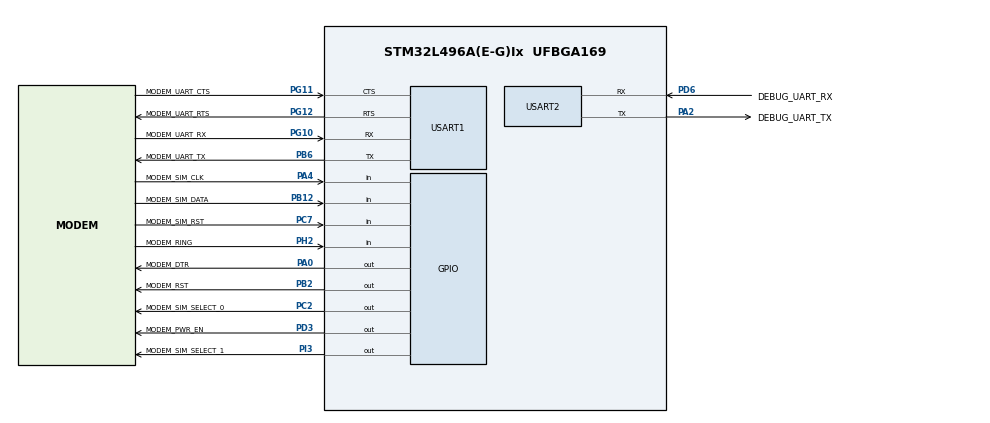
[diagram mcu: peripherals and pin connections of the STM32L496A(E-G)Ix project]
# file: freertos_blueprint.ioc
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FREERTOS.INCLUDE_vTaskDelayUntil=1
FREERTOS.MEMORY_ALLOCATION=0
FREERTOS.Tasks01=defaultTask,0,128,StartDefaultTask,Default,NULL,Dynamic,NULL,NULL
FREERTOS.configENABLE_BACKWARD_COMPATIBILITY=1
FREERTOS.configUSE_COUNTING_SEMAPHORES=1
FREERTOS.configUSE_NEWLIB_REENTRANT=0
FREERTOS.configUSE_TIMERS=1
FREERTOS.configUSE_TRACE_FACILITY=1
Mcu.Family=STM32L4
Mcu.Name=STM32L496A(E-G)Ix
Mcu.Package=UFBGA169
NVIC.PriorityGroup=NVIC_PRIORITYGROUP_4
NVIC.TIM6_DAC_IRQn=true\:0\:0\:true\:false\:true\:false\:false\:true\:true
NVIC.TimeBase=TIM6_DAC_IRQn
NVIC.TimeBaseIP=TIM6
NVIC.USART1_IRQn=true\:5\:0\:false\:false\:true\:true\:true\:true\:true
NVIC.USART2_IRQn=true\:5\:0\:false\:false\:true\:true\:true\:true\:true
PA0.GPIO_Label=MODEM_DTR
PA0.Signal=GPIO_Output
PA2.GPIO_Label=DEBUG_UART_TX
PA2.Mode=Asynchronous
PA2.Signal=USART2_TX
PA4.GPIO_Label=MODEM_SIM_CLK
PA4.Signal=GPIO_Input
PB12.GPIO_Label=MODEM_SIM_DATA
PB12.Signal=GPIO_Input
PB2.GPIO_Label=MODEM_RST
PB2.PinState=GPIO_PIN_SET
PB2.Signal=GPIO_Output
PB6.GPIO_Label=MODEM_UART_TX
PB6.Mode=Asynchronous
PB6.Signal=USART1_TX
PC2.GPIO_Label=MODEM_SIM_SELECT_0
PC2.Signal=GPIO_Output
PC7.GPIO_Label=MODEM_SIM_RST
PC7.Signal=GPIO_Input
PD3.GPIO_Label=MODEM_PWR_EN
PD3.PinState=GPIO_PIN_SET
PD3.Signal=GPIO_Output
PD6.GPIO_Label=DEBUG_UART_RX
PD6.Mode=Asynchronous
PD6.Signal=USART2_RX
PG10.GPIO_Label=MODEM_UART_RX
PG10.Mode=Asynchronous
PG10.Signal=USART1_RX
PG11.GPIO_Label=MODEM_UART_CTS
PG11.Mode=CTS_RTS
PG11.Signal=USART1_CTS
PG12.GPIO_Label=MODEM_UART_RTS
PG12.Mode=CTS_RTS
PG12.Signal=USART1_RTS
PH2.GPIO_Label=MODEM_RING
PH2.Signal=GPIO_Input
PI3.GPIO_Label=MODEM_SIM_SELECT_1
PI3.Signal=GPIO_Output
ProjectManager.HeapSize=0x200
ProjectManager.StackSize=0x400
ProjectManager.TargetToolchain=CMake
RCC.ADCFreq_Value=40000000
RCC.AHBFreq_Value=80000000
RCC.APB1Freq_Value=80000000
RCC.APB1TimFreq_Value=80000000
RCC.APB2Freq_Value=80000000
RCC.APB2TimFreq_Value=80000000
RCC.CortexFreq_Value=80000000
RCC.HCLKFreq_Value=80000000
RCC.HSE_VALUE=8000000
RCC.HSI48_VALUE=48000000
RCC.HSI_VALUE=16000000
RCC.LSE_VALUE=32768
RCC.MSI_VALUE=4000000
RCC.PLLN=40
RCC.PLLSAI1N=20
RCC.SYSCLKFreq_VALUE=80000000
RCC.SYSCLKSource=RCC_SYSCLKSOURCE_PLLCLK
RCC.USBFreq_Value=40000000
RCC.VCOOutputFreq_Value=160000000
USART1.VirtualMode-Asynchronous=VM_ASYNC
USART2.VirtualMode-Asynchronous=VM_ASYNC
VP_FREERTOS_VS_CMSIS_V1.Mode=CMSIS_V1
VP_RNG_VS_RNG.Mode=RNG_Activate
VP_RTC_VS_RTC_Activate.Mode=RTC_Enabled
VP_SYS_VS_tim6.Mode=TIM6
board=custom

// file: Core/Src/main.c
/* USER CODE BEGIN Header */

/**
 ******************************************************************************
 * @file           : main.c
 * @brief          : Main program body
 ******************************************************************************
 * @attention
 *
 * <h2><center>&copy; Copyright (c) 2020 STMicroelectronics.
 * All rights reserved.</center></h2>
 *
 * This software component is licensed by ST under Ultimate Liberty license
 * SLA0044, the "License"; You may not use this file except in compliance with
 * the License. You may obtain a copy of the License at:
 *                             www.st.com/SLA0044
 *
 ******************************************************************************
 */
/* USER CODE END Header */
#include "iot_config.h"

#include "main.h"
#include "stdint.h"
#include "stdarg.h"

/* FreeRTOS includes. */
#include "FreeRTOS.h"
#include "task.h"
/* Demo Includes*/
#include "cellular_app.h"

#ifdef IOT_LOG_LEVEL_MAIN
#else
    #ifdef IOT_LOG_LEVEL_GLOBAL
        #define LIBRARY_LOG_LEVEL    IOT_LOG_LEVEL_GLOBAL
    #else
        #define LIBRARY_LOG_LEVEL    IOT_LOG_DEBUG
    #endif
#endif
/*#include "cmsis_os.h" */
/*#include "i2c.h" */
#include "usart.h"
#include "rng.h"
#include "rtc.h"
#include "gpio.h"

#define MAX_RETRY_ATTEMPTS    5      /* Maximum number of retries */
#define RETRY_DELAY_MS        10000  /* Delay between retry attempts in milliseconds */

/* The SPI driver polls at a high priority. The logging task's priority must also
 * be high to be not be starved of CPU time. */
#define mainLOGGING_TASK_PRIORITY           ( configMAX_PRIORITIES )
#define mainLOGGING_TASK_STACK_SIZE         ( configMINIMAL_STACK_SIZE * 4 )
#define mainLOGGING_MESSAGE_QUEUE_LENGTH    ( 15 )
#define main_RUNNER_TASK_STACK_SIZE         ( configMINIMAL_STACK_SIZE * 8 )

/* Heap 2 size for malloc. */
#define HEAP2_SIZE    ( 27 * 1024 )
void vApplicationDaemonTaskStartupHook( void );
extern void RunDemoTask( void );
extern int setupCellular( void );

/**********************
* Global Variables
**********************/
RTC_HandleTypeDef xHrtc;
RNG_HandleTypeDef xHrng;
uint8_t payload_selector;

int32_t delay_publish = 60 * 1000;

static void SystemClock_Config( void );

/**
 * @brief Initializes the STM32L475 IoT node board.
 *
 * Initialization of clock, LEDs, RNG, RTC, and Cellular module.
 */
static void prvMiscInitialization( void );

/**
 * @brief Initializes the FreeRTOS heap.
 *
 * Heap_5 is being used because the RAM is not contiguous, therefore the heap
 * needs to be initialized.  See http://www.freertos.org/a00111.html
 */
static void prvInitializeHeap( void );

/* USER CODE END PD */

void SystemClock_Config( void );
void MX_FREERTOS_Init( void );

static void CellularDemoTask()
{
    bool retCellular = true;

    /* Setup cellular. */
    retCellular = setupCellular();

    if( !retCellular )
    {
        int retries = 0;

        /* Retry cellular setup with a maximum number of attempts */
        while( ( retries < MAX_RETRY_ATTEMPTS ) && ( !retCellular ) )
        {
            /* Set pin PD3 to high, signaling the attempt */
            HAL_GPIO_WritePin( GPIOD, GPIO_PIN_3, GPIO_PIN_SET );

            /* Delay between retries */
            HAL_Delay( RETRY_DELAY_MS );

            /* Attempt to set up the cellular connection */
            retCellular = setupCellular();

            retries++;
        }

        /* If still unsuccessful after retries, prompt user for manual intervention */
        if( !retCellular )
        {
            /* Optionally, reset the system if necessary (uncomment if used) */
            LogInfo( "System will reset to resolve the issue.\r\n" );
            HAL_NVIC_SystemReset();
            return;
        }
    }

/* Stop here if we fail to initialize cellular. */
    configASSERT( retCellular == true );

    LogInfo( "---- START DEMO : ----- .\r\n" );

    RunDemoTask();
}

int main( void )
{
    /* Perform any hardware initialization that does not require the RTOS to be
     * running.  */
    prvMiscInitialization();

    /* MCU Configuration--------------------------------------------------------*/

    /* Reset of all peripherals, Initializes the Flash interface and the Systick. */
    HAL_Init();

    /* Configure the system clock */
    SystemClock_Config();

    /* Create tasks that are not dependent on the Cellular being initialized. */
    xLoggingTaskInitialize( mainLOGGING_TASK_STACK_SIZE,
                            mainLOGGING_TASK_PRIORITY,
                            mainLOGGING_MESSAGE_QUEUE_LENGTH );

    /* Start the scheduler.  Initialization that requires the OS to be running,
     */
    vTaskStartScheduler();

    return 0;
}

/*-----------------------------------------------------------*/

void vApplicationDaemonTaskStartupHook( void )
{
    if( SYSTEM_Init() == pdPASS )
    {
        xTaskCreate( CellularDemoTask,            /* Function that implements the task. */
                     "CellularDemo",              /* Text name for the task - only used for debugging. */
                     main_RUNNER_TASK_STACK_SIZE, /* Size of stack (in words, not bytes) to allocate for the task. */
                     NULL,                        /* Task parameter - not used in this case. */
                     configMAX_PRIORITIES - 2,    /* Task priority, must be between 0 and configMAX_PRIORITIES - 1. */
                     NULL );                      /* Used to pass out a handle to the created task - not used in this case. */
    }
    else
    {
        IotLogError( "System failed to initialize.\r\n" );
        return;
    }
}
/*-----------------------------------------------------------*/

/**
 * @brief Initializes the board.
 */
static void prvMiscInitialization( void )
{
    /* Reset of all peripherals, Initializes the Flash interface and the Systick. */
    HAL_Init();

    /* Configure the system clock. */
    SystemClock_Config();

    /* Heap_5 is being used because the RAM is not contiguous in memory, so the
     * heap must be initialized. */
    prvInitializeHeap();

    /* Initialize all configured peripherals */
    MX_GPIO_Init();
    MX_USART2_UART_Init();

    /* Disable initialization of Modem-UART.
     * It will be enabled only when requested by upper layers.
     * MX_USART1_UART_Init();
     */
    MX_USART1_UART_Init();
    MX_RTC_Init();
    MX_RNG_Init();
}

/*-----------------------------------------------------------*/

/* Psuedo random number generator.  Just used by demos so does not need to be
 * secure.  Do not use the standard C library rand() function as it can cause
 * unexpected behaviour, such as calls to malloc(). */
int iMainRand32( void )
{
    static UBaseType_t uxlNextRand; /*_RB_ Not seeded. */
    const uint32_t ulMultiplier = 0x015a4e35UL, ulIncrement = 1UL;

    /* Utility function to generate a pseudo random number. */

    uxlNextRand = ( ulMultiplier * uxlNextRand ) + ulIncrement;

    return( ( int ) ( uxlNextRand >> 16UL ) & 0x7fffUL );
}

static void prvInitializeHeap( void )
{
    static uint8_t ucHeap1[ configTOTAL_HEAP_SIZE ];
    static uint8_t ucHeap2[ HEAP2_SIZE ] __attribute__( ( section( ".freertos_heap2" ) ) );

    HeapRegion_t xHeapRegions[] =
    {
        { ( unsigned char * ) ucHeap2, sizeof( ucHeap2 ) },
        { ( unsigned char * ) ucHeap1, sizeof( ucHeap1 ) },
        { NULL,                        0                 }
    };

    vPortDefineHeapRegions( xHeapRegions );
}

/*-----------------------------------------------------------*/

void SystemClock_Config( void )
{
    RCC_OscInitTypeDef RCC_OscInitStruct = { 0 };
    RCC_ClkInitTypeDef RCC_ClkInitStruct = { 0 };
    RCC_PeriphCLKInitTypeDef PeriphClkInit = { 0 };

    /** Initializes the CPU, AHB and APB busses clocks
     */
    RCC_OscInitStruct.OscillatorType = RCC_OSCILLATORTYPE_LSI | RCC_OSCILLATORTYPE_MSI;
    RCC_OscInitStruct.LSIState = RCC_LSI_ON;
    RCC_OscInitStruct.MSIState = RCC_MSI_ON;
    RCC_OscInitStruct.MSICalibrationValue = 0;
    RCC_OscInitStruct.MSIClockRange = RCC_MSIRANGE_6;
    RCC_OscInitStruct.PLL.PLLState = RCC_PLL_ON;
    RCC_OscInitStruct.PLL.PLLSource = RCC_PLLSOURCE_MSI;
    RCC_OscInitStruct.PLL.PLLM = 1;
    RCC_OscInitStruct.PLL.PLLN = 40;
    RCC_OscInitStruct.PLL.PLLP = RCC_PLLP_DIV2;
    RCC_OscInitStruct.PLL.PLLQ = RCC_PLLQ_DIV2;
    RCC_OscInitStruct.PLL.PLLR = RCC_PLLR_DIV2;

    if( HAL_RCC_OscConfig( &RCC_OscInitStruct ) != HAL_OK )
    {
        Error_Handler();
    }

    /** Initializes the CPU, AHB and APB busses clocks
     */
    RCC_ClkInitStruct.ClockType = RCC_CLOCKTYPE_HCLK | RCC_CLOCKTYPE_SYSCLK
                                  | RCC_CLOCKTYPE_PCLK1 | RCC_CLOCKTYPE_PCLK2;
    RCC_ClkInitStruct.SYSCLKSource = RCC_SYSCLKSOURCE_PLLCLK;
    RCC_ClkInitStruct.AHBCLKDivider = RCC_SYSCLK_DIV1;
    RCC_ClkInitStruct.APB1CLKDivider = RCC_HCLK_DIV1;
    RCC_ClkInitStruct.APB2CLKDivider = RCC_HCLK_DIV1;

    if( HAL_RCC_ClockConfig( &RCC_ClkInitStruct, FLASH_LATENCY_4 ) != HAL_OK )
    {
        Error_Handler();
    }

    PeriphClkInit.PeriphClockSelection = RCC_PERIPHCLK_RTC | RCC_PERIPHCLK_USART1
                                         | RCC_PERIPHCLK_USART2 | RCC_PERIPHCLK_LPUART1
                                         | RCC_PERIPHCLK_I2C1 | RCC_PERIPHCLK_RNG;

    PeriphClkInit.Usart1ClockSelection = RCC_USART1CLKSOURCE_PCLK2;
    PeriphClkInit.Usart2ClockSelection = RCC_USART2CLKSOURCE_PCLK1;
    PeriphClkInit.Lpuart1ClockSelection = RCC_LPUART1CLKSOURCE_PCLK1;
    PeriphClkInit.I2c1ClockSelection = RCC_I2C1CLKSOURCE_PCLK1;
    PeriphClkInit.RTCClockSelection = RCC_RTCCLKSOURCE_LSI;
    PeriphClkInit.RngClockSelection = RCC_RNGCLKSOURCE_PLLSAI1;
    PeriphClkInit.PLLSAI1.PLLSAI1Source = RCC_PLLSOURCE_MSI;
    PeriphClkInit.PLLSAI1.PLLSAI1M = 1;
    PeriphClkInit.PLLSAI1.PLLSAI1N = 20;
    PeriphClkInit.PLLSAI1.PLLSAI1P = RCC_PLLP_DIV2;
    PeriphClkInit.PLLSAI1.PLLSAI1Q = RCC_PLLQ_DIV2;
    PeriphClkInit.PLLSAI1.PLLSAI1R = RCC_PLLR_DIV2;
    PeriphClkInit.PLLSAI1.PLLSAI1ClockOut = RCC_PLLSAI1_48M2CLK;

    if( HAL_RCCEx_PeriphCLKConfig( &PeriphClkInit ) != HAL_OK )
    {
        Error_Handler();
    }

    /** Configure the main internal regulator output voltage
     */
    if( HAL_PWREx_ControlVoltageScaling( PWR_REGULATOR_VOLTAGE_SCALE1 ) != HAL_OK )
    {
        Error_Handler();
    }

    /**Configure the Systick interrupt time
     */
    HAL_SYSTICK_Config( HAL_RCC_GetHCLKFreq() / 1000 );

    /**Configure the Systick
     */
    HAL_SYSTICK_CLKSourceConfig( SYSTICK_CLKSOURCE_HCLK );

    /* SysTick_IRQn interrupt configuration */
    HAL_NVIC_SetPriority( SysTick_IRQn, 15, 0 );
}

/*-----------------------------------------------------------*/

void vApplicationIdleHook( void )
{
    static TickType_t xLastPrint = 0;
    TickType_t xTimeNow;
    const TickType_t xPrintFrequency = pdMS_TO_TICKS( 30000 );

    xTimeNow = xTaskGetTickCount();

    if( ( xTimeNow - xLastPrint ) > xPrintFrequency )
    {
        IotLogInfo( "." );
        xLastPrint = xTimeNow;
    }
}

void HAL_TIM_PeriodElapsedCallback( TIM_HandleTypeDef * htim )
{
    if( htim->Instance == TIM3 )
    {
        HAL_IncTick();
    }
}

void Error_Handler( void )
{
    while( 1 )
    {
    }
}

/************************ (C) COPYRIGHT STMicroelectronics *****END OF FILE****/

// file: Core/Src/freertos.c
/* USER CODE BEGIN Header */

/**
 ******************************************************************************
 * File Name          : freertos.c
 * Description        : Code for freertos applications
 ******************************************************************************
 * @attention
 *
 * Copyright (c) 2023 STMicroelectronics.
 * All rights reserved.
 *
 * This software is licensed under terms that can be found in the LICENSE file
 * in the root directory of this software component.
 * If no LICENSE file comes with this software, it is provided AS-IS.
 *
 ******************************************************************************
 */
/* USER CODE END Header */

#include "FreeRTOS.h"
#include "task.h"
#include "main.h"
#include "cmsis_os2.h"

/*-----------------------------------------------------------*/

/* configUSE_STATIC_ALLOCATION is set to 1, so the application must provide an
 * implementation of vApplicationGetIdleTaskMemory() to provide the memory that is
 * used by the Idle task. */
void vApplicationGetIdleTaskMemory( StaticTask_t ** ppxIdleTaskTCBBuffer,
                                    StackType_t ** ppxIdleTaskStackBuffer,
                                    uint32_t * pulIdleTaskStackSize )
{
    /* If the buffers to be provided to the Idle task are declared inside this
     * function then they must be declared static - otherwise they will be allocated on
     * the stack and so not exists after this function exits. */
    static StaticTask_t xIdleTaskTCB;
    static StackType_t uxIdleTaskStack[ configMINIMAL_STACK_SIZE ];

    /* Pass out a pointer to the StaticTask_t structure in which the Idle task's
     * state will be stored. */
    *ppxIdleTaskTCBBuffer = &xIdleTaskTCB;

    /* Pass out the array that will be used as the Idle task's stack. */
    *ppxIdleTaskStackBuffer = uxIdleTaskStack;

    /* Pass out the size of the array pointed to by *ppxIdleTaskStackBuffer.
     * Note that, as the array is necessarily of type StackType_t,
     * configMINIMAL_STACK_SIZE is specified in words, not bytes. */
    *pulIdleTaskStackSize = configMINIMAL_STACK_SIZE;
}

/*-----------------------------------------------------------*/

/* configUSE_STATIC_ALLOCATION and configUSE_TIMERS are both set to 1, so the
 * application must provide an implementation of vApplicationGetTimerTaskMemory()
 * to provide the memory that is used by the Timer service task. */
void vApplicationGetTimerTaskMemory( StaticTask_t ** ppxTimerTaskTCBBuffer,
                                     StackType_t ** ppxTimerTaskStackBuffer,
                                     uint32_t * pulTimerTaskStackSize )
{
    /* If the buffers to be provided to the Timer task are declared inside this
     * function then they must be declared static - otherwise they will be allocated on
     * the stack and so not exists after this function exits. */
    static StaticTask_t xTimerTaskTCB;
    static StackType_t uxTimerTaskStack[ configTIMER_TASK_STACK_DEPTH ];

    /* Pass out a pointer to the StaticTask_t structure in which the Timer
     * task's state will be stored. */
    *ppxTimerTaskTCBBuffer = &xTimerTaskTCB;

    /* Pass out the array that will be used as the Timer task's stack. */
    *ppxTimerTaskStackBuffer = uxTimerTaskStack;

    /* Pass out the size of the array pointed to by *ppxTimerTaskStackBuffer.
     * Note that, as the array is necessarily of type StackType_t,
     * configMINIMAL_STACK_SIZE is specified in words, not bytes. */
    *pulTimerTaskStackSize = configTIMER_TASK_STACK_DEPTH;
}

/*-----------------------------------------------------------*/

/* USER CODE BEGIN Includes */
extern void application_init( void );
extern void application_start( void );
/* USER CODE END Includes */

osThreadId_t defaultTaskHandle;

void StartDefaultTask( void const * argument );

void MX_FREERTOS_Init( void ); /* (MISRA C 2004 rule 8.1) */

void MX_FREERTOS_Init( void )
{

    /* USER CODE BEGIN RTOS_QUEUES */
    /* add queues, ... */
    #if 0 /* disable defaultTask */
        /* USER CODE END RTOS_QUEUES */

        /* Create the thread(s) */
        /* definition and creation of defaultTask */
        osThreadDef( defaultTask, StartDefaultTask, osPriorityNormal, 0, 128 );
        defaultTaskHandle = osThreadCreate( osThread( defaultTask ), NULL );

        /* USER CODE BEGIN RTOS_THREADS */
    #endif /* disable defaultTask */
    /* add threads, ... */
    application_init();
    application_start();
    /* USER CODE END RTOS_THREADS */
}

void StartDefaultTask( void const * argument )
{
    /* USER CODE BEGIN StartDefaultTask */
    /* Infinite loop */
    for( ;; )
    {
        osDelay( 1 );
    }

    /* USER CODE END StartDefaultTask */
}
